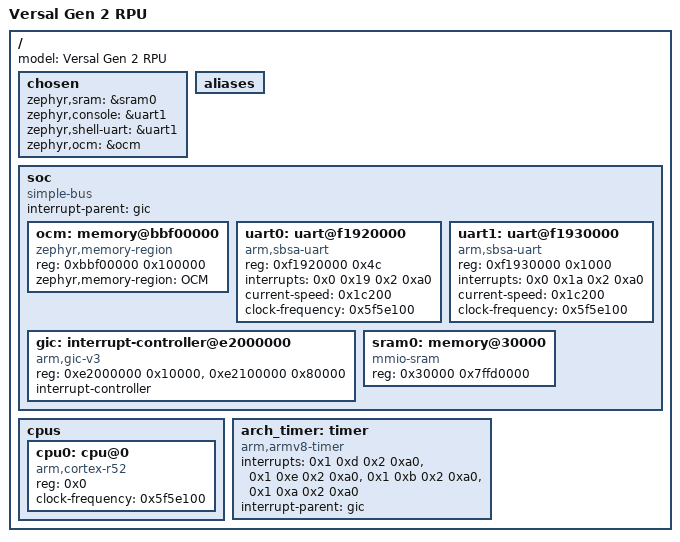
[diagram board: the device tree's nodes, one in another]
/dts-v1/;

/* node '/' defined in zephyr/dts/common/skeleton.dtsi:9 */
/ {
	#address-cells = < 0x1 >;   /* in zephyr/dts/common/skeleton.dtsi:10 */
	#size-cells = < 0x1 >;      /* in zephyr/dts/common/skeleton.dtsi:11 */
	model = "Versal Gen 2 RPU"; /* in zephyr/dts/arm/xilinx/versal2_r52.dtsi:15 */

	/* node '/chosen' defined in zephyr/dts/common/skeleton.dtsi:13 */
	chosen {
		zephyr,sram = &sram0;       /* in zephyr/boards/amd/versal2_rpu/versal2_rpu.dts:12 */
		zephyr,console = &uart1;    /* in zephyr/boards/amd/versal2_rpu/versal2_rpu.dts:13 */
		zephyr,shell-uart = &uart1; /* in zephyr/boards/amd/versal2_rpu/versal2_rpu.dts:14 */
		zephyr,ocm = &ocm;          /* in zephyr/boards/amd/versal2_rpu/versal2_rpu.dts:15 */
	};

	/* node '/aliases' defined in zephyr/dts/common/skeleton.dtsi:15 */
	aliases {
	};

	/* node '/soc' defined in zephyr/dts/arm/armv8-r.dtsi:10 */
	soc: soc {
		#address-cells = < 0x1 >;    /* in zephyr/dts/arm/armv8-r.dtsi:11 */
		#size-cells = < 0x1 >;       /* in zephyr/dts/arm/armv8-r.dtsi:12 */
		compatible = "simple-bus";   /* in zephyr/dts/arm/armv8-r.dtsi:13 */
		ranges;                      /* in zephyr/dts/arm/armv8-r.dtsi:14 */
		interrupt-parent = < &gic >; /* in zephyr/dts/arm/xilinx/versal2_r52.dtsi:40 */

		/* node '/soc/memory@bbf00000' defined in zephyr/dts/vendor/amd/versal2.dtsi:9 */
		ocm: memory@bbf00000 {
			compatible = "zephyr,memory-region"; /* in zephyr/dts/vendor/amd/versal2.dtsi:10 */
			reg = < 0xbbf00000 0x100000 >;       /* in zephyr/dts/vendor/amd/versal2.dtsi:11 */
			zephyr,memory-region = "OCM";        /* in zephyr/dts/vendor/amd/versal2.dtsi:13 */
			status = "okay";                     /* in zephyr/boards/amd/versal2_rpu/versal2_rpu.dts:31 */
		};

		/* node '/soc/uart@f1920000' defined in zephyr/dts/vendor/amd/versal2.dtsi:16 */
		uart0: uart@f1920000 {
			compatible = "arm,sbsa-uart";       /* in zephyr/dts/vendor/amd/versal2.dtsi:17 */
			reg = < 0xf1920000 0x4c >;          /* in zephyr/dts/vendor/amd/versal2.dtsi:18 */
			interrupt-names = "irq_0";          /* in zephyr/dts/vendor/amd/versal2.dtsi:20 */
			interrupts = < 0x0 0x19 0x2 0xa0 >; /* in zephyr/dts/vendor/amd/versal2.dtsi:21 */
			status = "okay";                    /* in zephyr/boards/amd/versal2_rpu/versal2_rpu.dts:41 */
			current-speed = < 0x1c200 >;        /* in zephyr/boards/amd/versal2_rpu/versal2_rpu.dts:42 */
			clock-frequency = < 0x5f5e100 >;    /* in zephyr/boards/amd/versal2_rpu/versal2_rpu.dts:43 */
		};

		/* node '/soc/uart@f1930000' defined in zephyr/dts/vendor/amd/versal2.dtsi:24 */
		uart1: uart@f1930000 {
			compatible = "arm,sbsa-uart";       /* in zephyr/dts/vendor/amd/versal2.dtsi:25 */
			reg = < 0xf1930000 0x1000 >;        /* in zephyr/dts/vendor/amd/versal2.dtsi:26 */
			interrupt-names = "irq_1";          /* in zephyr/dts/vendor/amd/versal2.dtsi:28 */
			interrupts = < 0x0 0x1a 0x2 0xa0 >; /* in zephyr/dts/vendor/amd/versal2.dtsi:29 */
			status = "okay";                    /* in zephyr/boards/amd/versal2_rpu/versal2_rpu.dts:35 */
			current-speed = < 0x1c200 >;        /* in zephyr/boards/amd/versal2_rpu/versal2_rpu.dts:36 */
			clock-frequency = < 0x5f5e100 >;    /* in zephyr/boards/amd/versal2_rpu/versal2_rpu.dts:37 */
		};

		/* node '/soc/interrupt-controller@e2000000' defined in zephyr/dts/arm/xilinx/versal2_r52.dtsi:42 */
		gic: interrupt-controller@e2000000 {
			compatible = "arm,gic-v3",
			             "arm,gic";       /* in zephyr/dts/arm/xilinx/versal2_r52.dtsi:43 */
			reg = < 0xe2000000 0x10000 >,
			      < 0xe2100000 0x80000 >; /* in zephyr/dts/arm/xilinx/versal2_r52.dtsi:44 */
			interrupt-controller;         /* in zephyr/dts/arm/xilinx/versal2_r52.dtsi:45 */
			#interrupt-cells = < 0x4 >;   /* in zephyr/dts/arm/xilinx/versal2_r52.dtsi:46 */
			status = "okay";              /* in zephyr/dts/arm/xilinx/versal2_r52.dtsi:47 */
			phandle = < 0x1 >;            /* in zephyr/dts/arm/xilinx/versal2_r52.dtsi:40 */
		};

		/* node '/soc/memory@30000' defined in zephyr/boards/amd/versal2_rpu/versal2_rpu.dts:24 */
		sram0: memory@30000 {
			compatible = "mmio-sram";     /* in zephyr/boards/amd/versal2_rpu/versal2_rpu.dts:25 */
			reg = < 0x30000 0x7ffd0000 >; /* in zephyr/boards/amd/versal2_rpu/versal2_rpu.dts:26 */
		};
	};

	/* node '/cpus' defined in zephyr/dts/arm/xilinx/versal2_r52.dtsi:17 */
	cpus {
		#address-cells = < 0x1 >; /* in zephyr/dts/arm/xilinx/versal2_r52.dtsi:18 */
		#size-cells = < 0x0 >;    /* in zephyr/dts/arm/xilinx/versal2_r52.dtsi:19 */

		/* node '/cpus/cpu@0' defined in zephyr/dts/arm/xilinx/versal2_r52.dtsi:21 */
		cpu0: cpu@0 {
			device_type = "cpu";             /* in zephyr/dts/arm/xilinx/versal2_r52.dtsi:22 */
			compatible = "arm,cortex-r52";   /* in zephyr/dts/arm/xilinx/versal2_r52.dtsi:23 */
			reg = < 0x0 >;                   /* in zephyr/dts/arm/xilinx/versal2_r52.dtsi:24 */
			clock-frequency = < 0x5f5e100 >; /* in zephyr/boards/amd/versal2_rpu/versal2_rpu.dts:20 */
		};
	};

	/* node '/timer' defined in zephyr/dts/arm/xilinx/versal2_r52.dtsi:28 */
	arch_timer: timer {
		compatible = "arm,armv8-timer";    /* in zephyr/dts/arm/xilinx/versal2_r52.dtsi:29 */
		interrupts = < 0x1 0xd 0x2 0xa0 >,
		             < 0x1 0xe 0x2 0xa0 >,
		             < 0x1 0xb 0x2 0xa0 >,
		             < 0x1 0xa 0x2 0xa0 >; /* in zephyr/dts/arm/xilinx/versal2_r52.dtsi:30 */
		interrupt-parent = < &gic >;       /* in zephyr/dts/arm/xilinx/versal2_r52.dtsi:34 */
		status = "okay";                   /* in zephyr/dts/arm/xilinx/versal2_r52.dtsi:35 */
	};
};
